# STM32L0x3 register map
File version: 1.7
CPU: CM0+ r0p0, little endian, MPU, no FPU, 2 interrupt priority bits
Registers are 32-bit, read-write, reset 0x0 unless marked. A register's access mark holds for its fields unless they carry their own. Offsets are from the block's base; [hi:lo] are bit positions; {n}, {i} and the like mark numbered series.

## USB — Universal serial bus full-speed device interface
Base 0x40005C00
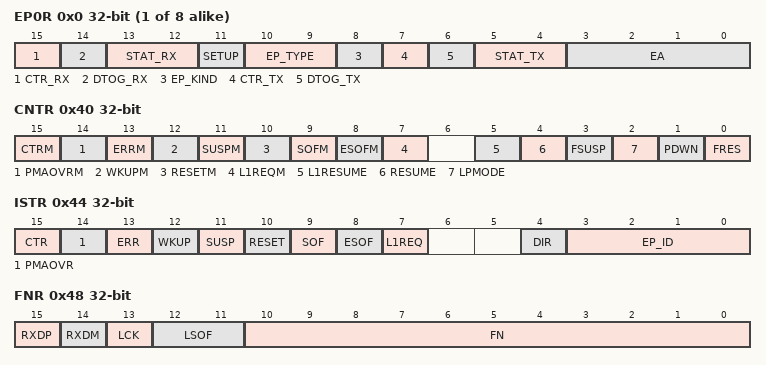
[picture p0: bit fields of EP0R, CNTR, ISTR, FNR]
{0x0+4i} EP{i}R (i=0..7) — endpoint register
  [15] CTR_RX write-0-clears
  [14] DTOG_RX write-1-toggles
  [13:12] STAT_RX write-1-toggles
    on read: 0=Disabled (all reception requests addressed to this endpoint are ignored); 1=Stall (the endpoint is stalled and all reception requests result in a STALL handshake); 2=Nak (the endpoint is naked and all reception requests result in a NAK handshake); 3=Valid (this endpoint is enabled for reception)
  [11] SETUP
  [10:9] EP_TYPE
    0=Bulk endpoint; 1=Control endpoint; 2=Iso (Iso endpoint); 3=Interrupt endpoint
  [8] EP_KIND
  [7] CTR_TX write-0-clears
  [6] DTOG_TX write-1-toggles
  [5:4] STAT_TX write-1-toggles
    on read: 0=Disabled (all transmission requests addressed to this endpoint are ignored); 1=Stall (the endpoint is stalled and all transmission requests result in a STALL handshake); 2=Nak (the endpoint is naked and all transmission requests result in a NAK handshake); 3=Valid (this endpoint is enabled for transmission)
  [3:0] EA
0x40 CNTR — control register
  [15] CTRM
    0=Disabled (Correct Transfer (CTR) Interrupt disabled); 1=Enabled (CTR Interrupt enabled, an interrupt request is generated when the corresponding bit in the USB_ISTR register is set)
  [14] PMAOVRM
    0=Disabled (PMAOVR Interrupt disabled); 1=Enabled (PMAOVR Interrupt enabled, an interrupt request is generated when the corresponding bit in the USB_ISTR register is set)
  [13] ERRM
    0=Disabled (ERR Interrupt disabled); 1=Enabled (ERR Interrupt enabled, an interrupt request is generated when the corresponding bit in the USB_ISTR register is set)
  [12] WKUPM
    0=Disabled (WKUP Interrupt disabled); 1=Enabled (WKUP Interrupt enabled, an interrupt request is generated when the corresponding bit in the USB_ISTR register is set)
  [11] SUSPM
    0=Disabled (Suspend Mode Request SUSP Interrupt disabled); 1=Enabled (SUSP Interrupt enabled, an interrupt request is generated when the corresponding bit in the USB_ISTR register is set)
  [10] RESETM
    0=Disabled (RESET Interrupt disabled); 1=Enabled (RESET Interrupt enabled, an interrupt request is generated when the corresponding bit in the USB_ISTR register is set)
  [9] SOFM
    0=Disabled (SOF Interrupt disabled); 1=Enabled (SOF Interrupt enabled, an interrupt request is generated when the corresponding bit in the USB_ISTR register is set)
  [8] ESOFM
    0=Disabled (ESOF Interrupt disabled); 1=Enabled (ESOF Interrupt enabled, an interrupt request is generated when the corresponding bit in the USB_ISTR register is set)
  [7] L1REQM
    0=Disabled (L1REQ Interrupt disabled); 1=Enabled (L1REQ Interrupt enabled, an interrupt request is generated when the corresponding bit in the USB_ISTR register is set)
  [5] L1RESUME
    1=Requested (LPM L1 request requested)
  [4] RESUME
    1=Requested (Resume requested)
  [3] FSUSP
    0=NoEffect; 1=Suspend (Enter suspend mode. Clocks and static power dissipation in the analog transceiver are left unaffected)
  [2] LPMODE
    0=Disabled (No low-power mode); 1=Enabled (Enter low-power mode)
  [1] PDWN
    0=Disabled (No power down); 1=Enabled (Enter power down mode)
  [0] FRES
    0=NoReset (Clear USB reset); 1=Reset (Force a reset of the USB peripheral, exactly like a RESET signaling on the USB)
0x44 ISTR — interrupt status register
  [15] CTR
    1=Completed (Endpoint has successfully completed a transaction)
  [14] PMAOVR write-0-clears
    on read: 0=NotOverrun (Overrun is not occurred); 1=Overrun (Microcontroller has not been able to respond in time to an USB memory request) | on write: 0=Clear flag
  [13] ERR write-0-clears
    on read: 0=NotOverrun (Errors are not occurred); 1=Error (One of No ANSwer, Cyclic Redundancy Check, Bit Stuffing or Framing format Violation error occurred) | on write: 0=Clear flag
  [12] WKUP write-0-clears
    on read: 0=NotWakeup; 1=Wakeup (Activity is detected that wakes up the USB peripheral) | on write: 0=Clear flag
  [11] SUSP write-0-clears
    on read: 0=NotSuspend; 1=Suspend (No traffic has been received for 3 ms, indicating a suspend mode request from the USB bus) | on write: 0=Clear flag
  [10] RESET write-0-clears
    on read: 0=NotReset; 1=Reset (Peripheral detects an active USB RESET signal at its inputs) | on write: 0=Clear flag
  [9] SOF write-0-clears
    on read: 0=NotStartOfFrame; 1=StartOfFrame (Beginning of a new USB frame and it is set when a SOF packet arrives through the USB bus) | on write: 0=Clear flag
  [8] ESOF write-0-clears
    on read: 0=NotExpectedStartOfFrame; 1=ExpectedStartOfFrame (An SOF packet is expected but not received) | on write: 0=Clear flag
  [7] L1REQ write-0-clears
    on read: 0=NotReceived (LPM command to enter the L1 state is not received); 1=Received (LPM command to enter the L1 state is successfully received and acknowledged) | on write: 0=Clear flag
  [4] DIR
    0=To (Data transmitted by the USB peripheral to the host PC); 1=From (Data received by the USB peripheral from the host PC)
  [3:0] EP_ID
0x48 FNR ro — frame number register
  [15] RXDP
    1=received data plus upstream port data line
  [14] RXDM
    1=received data minus upstream port data line
  [13] LCK
    1=Locked (the frame timer remains in this state until an USB reset or USB suspend event occurs)
  [12:11] LSOF
  [10:0] FN
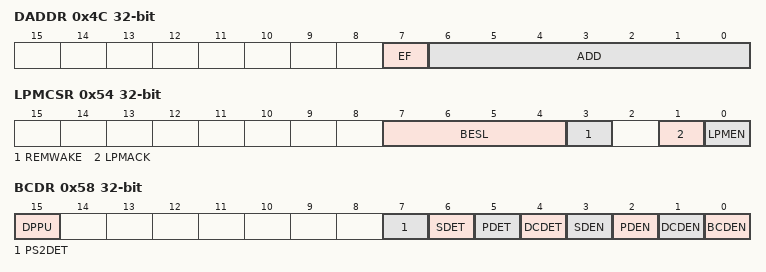
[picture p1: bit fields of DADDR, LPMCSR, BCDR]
0x4C DADDR — device address
  [7] EF
    0=Disabled (USB device disabled); 1=Enabled (USB device enabled)
  [6:0] ADD
0x50 BTABLE — Buffer table address
  [15:3] BTABLE
0x54 LPMCSR access per field — LPM control and status register
  [7:4] BESL ro
  [3] REMWAKE ro
  [1] LPMACK rw
    0=Nyet (The valid LPM Token will be NYET); 1=Ack (The valid LPM Token will be ACK)
  [0] LPMEN rw
    0=Disabled (No LPM transactions are handled); 1=Enabled (Enable the LPM support within the USB device)
0x58 BCDR access per field — Battery charging detector
  [15] DPPU rw
    0=Disabled (signalize disconnect to the host when needed by the user software); 1=Enabled (enable the embedded pull-up on the DP line)
  [7] PS2DET ro
    0=Normal port detected; 1=PS2 (PS2 port or proprietary charger detected)
  [6] SDET ro
    0=CDP (CDP detected); 1=DCP (DCP detected)
  [5] PDET ro
    0=no BCD support detected; 1=BCD (BCD support detected)
  [4] DCDET ro
    0=NotDetected (data lines contact not detected); 1=Detected (data lines contact detected)
  [3] SDEN rw
    0=Disabled (Secondary detection (SD) mode disabled); 1=Enabled (Secondary detection (SD) mode enabled)
  [2] PDEN rw
    0=Disabled (Primary detection (PD) mode disabled); 1=Enabled (Primary detection (PD) mode enabled)
  [1] DCDEN rw
    0=Disabled (Data contact detection (DCD) mode disabled); 1=Enabled (Data contact detection (DCD) mode enabled)
  [0] BCDEN rw
    0=Disabled (disable the BCD support); 1=Enabled (enable the BCD support within the USB device)
